VERSION ""

NS_ :

BS_:

BU_: INTERCEPTOR EON XXX

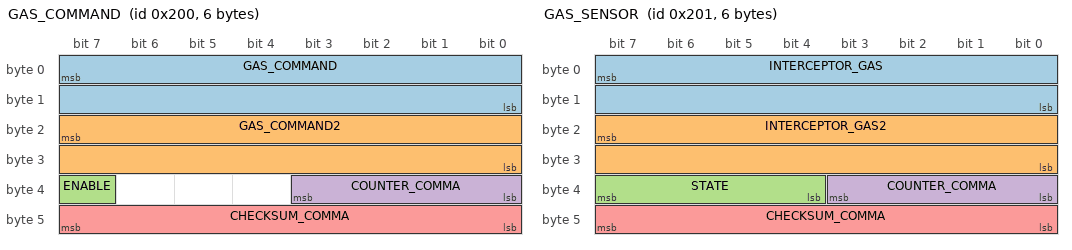
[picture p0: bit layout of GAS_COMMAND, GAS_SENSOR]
BO_ 512 GAS_COMMAND: 6 EON
 SG_ GAS_COMMAND : 7|16@0+ (0.253984064,-83.3) [0|1] "" INTERCEPTOR
 SG_ GAS_COMMAND2 : 23|16@0+ (0.126992032,-83.3) [0|1] "" INTERCEPTOR
 SG_ ENABLE : 39|1@0+ (1,0) [0|1] "" INTERCEPTOR
 SG_ COUNTER_COMMA : 35|4@0+ (1,0) [0|15] "" INTERCEPTOR
 SG_ CHECKSUM_COMMA : 47|8@0+ (1,0) [0|255] "" INTERCEPTOR

BO_ 513 GAS_SENSOR: 6 INTERCEPTOR
 SG_ INTERCEPTOR_GAS : 7|16@0+ (0.253984064,-83.3) [0|1] "" EON
 SG_ INTERCEPTOR_GAS2 : 23|16@0+ (0.126992032,-83.3) [0|1] "" EON
 SG_ STATE : 39|4@0+ (1,0) [0|15] "" EON
 SG_ COUNTER_COMMA : 35|4@0+ (1,0) [0|15] "" EON
 SG_ CHECKSUM_COMMA : 47|8@0+ (1,0) [0|255] "" EON

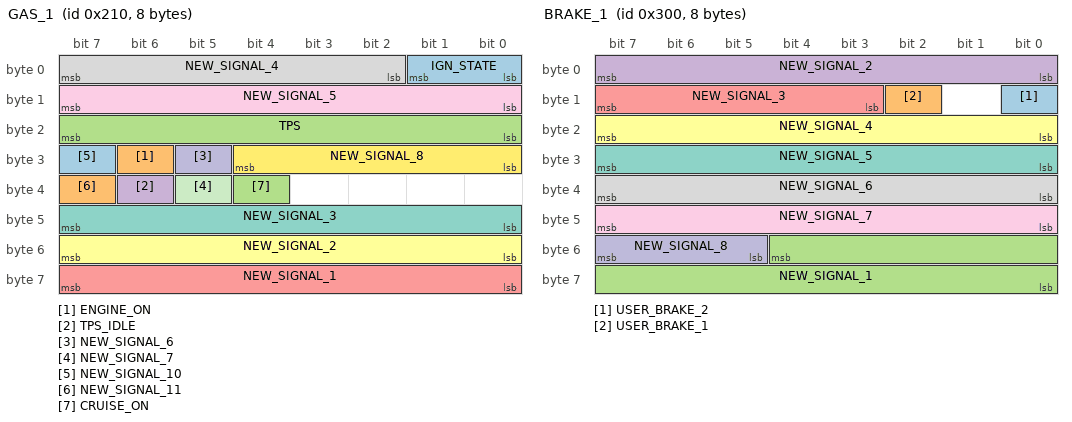
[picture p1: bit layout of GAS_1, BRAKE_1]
BO_ 528 GAS_1: 8 XXX
 SG_ IGN_STATE : 1|2@0+ (1,0) [0|1] "" XXX
 SG_ ENGINE_ON : 30|1@0+ (1,0) [0|1] "" XXX
 SG_ TPS : 23|8@0+ (1,0) [0|250] "" XXX
 SG_ TPS_IDLE : 38|1@0+ (1,0) [0|1] "" XXX
 SG_ NEW_SIGNAL_1 : 63|8@0+ (1,0) [0|1] "" XXX
 SG_ NEW_SIGNAL_2 : 55|8@0+ (1,0) [0|1] "" XXX
 SG_ NEW_SIGNAL_3 : 47|8@0+ (1,0) [0|1] "" XXX
 SG_ NEW_SIGNAL_4 : 7|6@0+ (1,0) [0|1] "" XXX
 SG_ NEW_SIGNAL_5 : 15|8@0+ (1,0) [0|1] "" XXX
 SG_ NEW_SIGNAL_6 : 29|1@0+ (1,0) [0|1] "" XXX
 SG_ NEW_SIGNAL_7 : 37|1@0+ (1,0) [0|1] "" XXX
 SG_ NEW_SIGNAL_8 : 28|5@0+ (1,0) [0|1] "" XXX
 SG_ NEW_SIGNAL_10 : 31|1@0+ (1,0) [0|1] "" XXX
 SG_ NEW_SIGNAL_11 : 39|1@0+ (1,0) [0|1] "" XXX
 SG_ CRUISE_ON : 36|1@0+ (1,0) [0|1] "" XXX

BO_ 768 BRAKE_1: 8 XXX
 SG_ USER_BRAKE_2 : 8|1@0+ (1,0) [0|1] "" XXX
 SG_ USER_BRAKE_1 : 10|1@1+ (1,0) [0|7] "" XXX
 SG_ NEW_SIGNAL_1 : 52|13@0- (1,0) [0|65535] "" XXX
 SG_ NEW_SIGNAL_2 : 7|8@0+ (1,0) [0|1] "" XXX
 SG_ NEW_SIGNAL_3 : 15|5@0+ (1,0) [0|1] "" XXX
 SG_ NEW_SIGNAL_4 : 23|8@0+ (1,0) [0|1] "" XXX
 SG_ NEW_SIGNAL_5 : 31|8@0+ (1,0) [0|1] "" XXX
 SG_ NEW_SIGNAL_6 : 39|8@0+ (1,0) [0|1] "" XXX
 SG_ NEW_SIGNAL_7 : 47|8@0+ (1,0) [0|1] "" XXX
 SG_ NEW_SIGNAL_8 : 55|3@0+ (1,0) [0|1] "" XXX

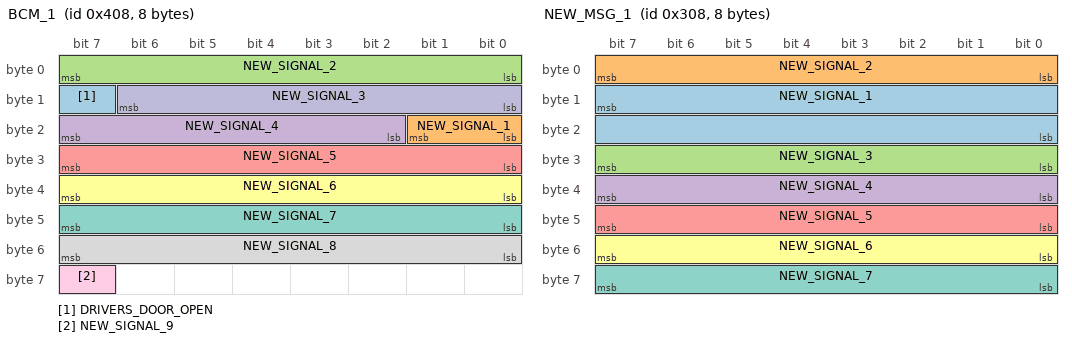
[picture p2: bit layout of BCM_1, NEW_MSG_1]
BO_ 1032 BCM_1: 8 XXX
 SG_ DRIVERS_DOOR_OPEN : 15|1@0+ (1,0) [0|1] "" XXX
 SG_ NEW_SIGNAL_1 : 16|2@1+ (1,0) [0|3] "" XXX
 SG_ NEW_SIGNAL_2 : 7|8@0+ (1,0) [0|1] "" XXX
 SG_ NEW_SIGNAL_4 : 23|6@0+ (1,0) [0|1] "" XXX
 SG_ NEW_SIGNAL_5 : 31|8@0+ (1,0) [0|1] "" XXX
 SG_ NEW_SIGNAL_6 : 39|8@0+ (1,0) [0|1] "" XXX
 SG_ NEW_SIGNAL_7 : 47|8@0+ (1,0) [0|1] "" XXX
 SG_ NEW_SIGNAL_8 : 55|8@0+ (1,0) [0|1] "" XXX
 SG_ NEW_SIGNAL_9 : 63|1@0+ (1,0) [0|1] "" XXX
 SG_ NEW_SIGNAL_3 : 14|7@0+ (1,0) [0|1] "" XXX

BO_ 1048 TRANS_1: 8 XXX
 SG_ NEW_SIGNAL_1 : 47|8@0+ (1,0) [0|16777215] "" XXX
 SG_ NEW_SIGNAL_3 : 53|6@0+ (1,0) [0|255] "" XXX
 SG_ NEW_SIGNAL_4 : 23|8@0+ (1,0) [0|255] "" XXX
 SG_ NEW_SIGNAL_6 : 31|8@0+ (1,0) [0|1] "" XXX
 SG_ NEW_SIGNAL_5 : 39|8@0+ (1,0) [0|1] "" XXX
 SG_ MODE_ASCII : 15|8@0+ (1,0) [0|255] "" XXX
 SG_ GEAR_ASCII : 7|8@0+ (1,0) [0|1] "" XXX
 SG_ NEW_SIGNAL_2 : 63|10@0+ (1,0) [0|255] "" XXX

BO_ 776 NEW_MSG_1: 8 XXX
 SG_ NEW_SIGNAL_1 : 15|16@0+ (1,0) [0|65535] "" XXX
 SG_ NEW_SIGNAL_2 : 7|8@0+ (1,0) [0|1] "" XXX
 SG_ NEW_SIGNAL_3 : 31|8@0+ (1,0) [0|1] "" XXX
 SG_ NEW_SIGNAL_4 : 39|8@0+ (1,0) [0|1] "" XXX
 SG_ NEW_SIGNAL_5 : 47|8@0+ (1,0) [0|1] "" XXX
 SG_ NEW_SIGNAL_6 : 55|8@0+ (1,0) [0|1] "" XXX
 SG_ NEW_SIGNAL_7 : 63|8@0+ (1,0) [0|1] "" XXX

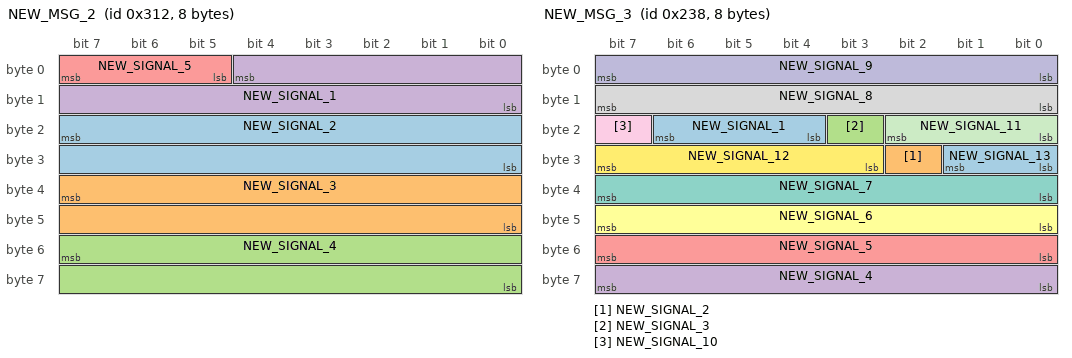
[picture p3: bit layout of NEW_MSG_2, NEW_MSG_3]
BO_ 786 NEW_MSG_2: 8 XXX
 SG_ NEW_SIGNAL_2 : 23|16@0+ (1,0) [0|65535] "" XXX
 SG_ NEW_SIGNAL_3 : 39|16@0+ (1,0) [0|65535] "" XXX
 SG_ NEW_SIGNAL_4 : 55|16@0+ (-1,0) [0|65535] "" XXX
 SG_ NEW_SIGNAL_1 : 4|13@0- (1,0) [0|65535] "" XXX
 SG_ NEW_SIGNAL_5 : 7|3@0+ (1,0) [0|1] "" XXX

BO_ 568 NEW_MSG_3: 8 XXX
 SG_ NEW_SIGNAL_1 : 22|3@0+ (1,0) [0|255] "" XXX
 SG_ NEW_SIGNAL_2 : 26|1@0+ (1,0) [0|1] "" XXX
 SG_ NEW_SIGNAL_3 : 19|1@0+ (1,0) [0|1] "" XXX
 SG_ NEW_SIGNAL_4 : 63|8@0+ (1,0) [0|255] "" XXX
 SG_ NEW_SIGNAL_5 : 55|8@0+ (1,0) [0|1] "" XXX
 SG_ NEW_SIGNAL_6 : 47|8@0+ (1,0) [0|1] "" XXX
 SG_ NEW_SIGNAL_7 : 39|8@0+ (1,0) [0|1] "" XXX
 SG_ NEW_SIGNAL_8 : 15|8@0+ (1,0) [0|1] "" XXX
 SG_ NEW_SIGNAL_10 : 23|1@0+ (1,0) [0|1] "" XXX
 SG_ NEW_SIGNAL_9 : 7|8@0+ (1,0) [0|1] "" XXX
 SG_ NEW_SIGNAL_11 : 18|3@0+ (1,0) [0|1] "" XXX
 SG_ NEW_SIGNAL_12 : 31|5@0+ (1,0) [0|1] "" XXX
 SG_ NEW_SIGNAL_13 : 25|2@0+ (1,0) [0|1] "" XXX

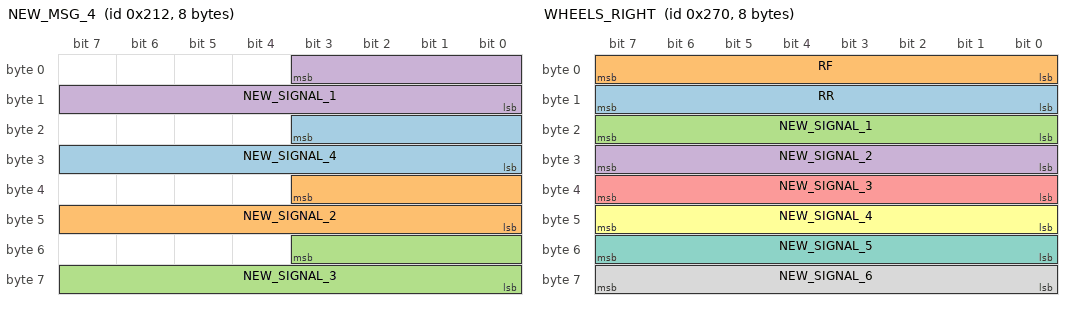
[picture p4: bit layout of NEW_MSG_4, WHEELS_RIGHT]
BO_ 530 NEW_MSG_4: 8 XXX
 SG_ NEW_SIGNAL_4 : 19|12@0+ (1,0) [0|65535] "" XXX
 SG_ NEW_SIGNAL_2 : 35|12@0+ (1,0) [0|65535] "" XXX
 SG_ NEW_SIGNAL_3 : 51|12@0+ (1,0) [0|15] "" XXX
 SG_ NEW_SIGNAL_1 : 3|12@0+ (1,0) [0|255] "" XXX

BO_ 520 NEW_MSG_5: 8 XXX
 SG_ NEW_SIGNAL_1 : 23|16@0+ (1,0) [0|65535] "" XXX
 SG_ NEW_SIGNAL_3 : 39|16@0+ (1,0) [0|65535] "" XXX
 SG_ NEW_SIGNAL_2 : 55|18@0+ (1,0) [0|255] "" XXX
 SG_ NEW_SIGNAL_4 : 7|16@0+ (1,0) [0|65535] "" XXX

BO_ 824 NEW_MSG_6: 8 XXX
 SG_ NEW_SIGNAL_1 : 51|14@0- (1,0) [0|65535] "" XXX
 SG_ NEW_SIGNAL_3 : 15|8@0+ (1,0) [0|1] "" XXX
 SG_ NEW_SIGNAL_4 : 23|8@0+ (1,0) [0|1] "" XXX
 SG_ NEW_SIGNAL_5 : 31|8@0+ (1,0) [0|1] "" XXX
 SG_ NEW_SIGNAL_6 : 39|8@0+ (1,0) [0|1] "" XXX
 SG_ NEW_SIGNAL_7 : 47|8@0+ (1,0) [0|1] "" XXX
 SG_ NEW_SIGNAL_8 : 55|4@0+ (1,0) [0|1] "" XXX
 SG_ NEW_SIGNAL_9 : 7|8@0+ (1,0) [0|255] "" XXX

BO_ 624 WHEELS_RIGHT: 8 XXX
 SG_ RR : 15|8@0+ (1,0) [0|257] "" XXX
 SG_ RF : 7|8@0+ (1,0) [0|255] "" XXX
 SG_ NEW_SIGNAL_1 : 23|8@0+ (1,0) [0|1] "" XXX
 SG_ NEW_SIGNAL_2 : 31|8@0+ (1,0) [0|1] "" XXX
 SG_ NEW_SIGNAL_3 : 39|8@0+ (1,0) [0|1] "" XXX
 SG_ NEW_SIGNAL_4 : 47|8@0+ (1,0) [0|1] "" XXX
 SG_ NEW_SIGNAL_5 : 55|8@0+ (1,0) [0|1] "" XXX
 SG_ NEW_SIGNAL_6 : 63|8@0+ (1,0) [0|1] "" XXX

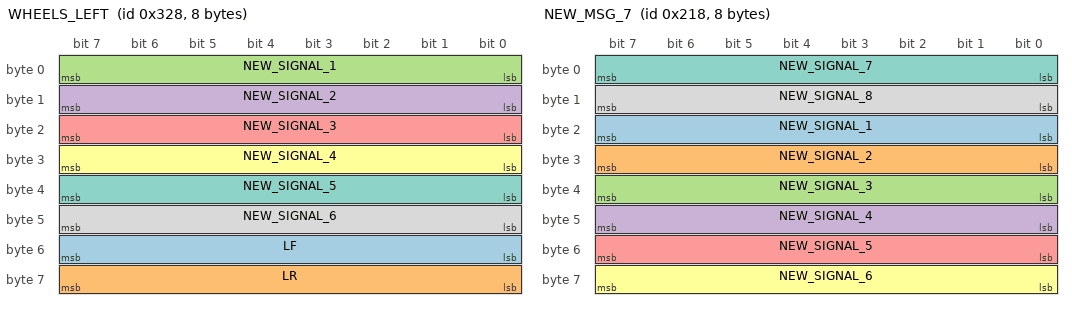
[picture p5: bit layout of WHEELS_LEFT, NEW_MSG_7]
BO_ 808 WHEELS_LEFT: 8 XXX
 SG_ LF : 55|8@0+ (1,0) [0|255] "" XXX
 SG_ LR : 63|8@0+ (1,0) [0|255] "" XXX
 SG_ NEW_SIGNAL_1 : 7|8@0+ (1,0) [0|1] "" XXX
 SG_ NEW_SIGNAL_2 : 15|8@0+ (1,0) [0|1] "" XXX
 SG_ NEW_SIGNAL_3 : 23|8@0+ (1,0) [0|1] "" XXX
 SG_ NEW_SIGNAL_4 : 31|8@0+ (1,0) [0|1] "" XXX
 SG_ NEW_SIGNAL_5 : 39|8@0+ (1,0) [0|1] "" XXX
 SG_ NEW_SIGNAL_6 : 47|8@0+ (1,0) [0|1] "" XXX

BO_ 560 BRAKE_2: 1 XXX
 SG_ NEW_SIGNAL_1 : 7|8@0+ (1,0) [0|255] "" XXX

BO_ 536 NEW_MSG_7: 8 XXX
 SG_ NEW_SIGNAL_1 : 23|8@0+ (1,0) [0|255] "" XXX
 SG_ NEW_SIGNAL_2 : 31|8@0+ (1,0) [0|65535] "" XXX
 SG_ NEW_SIGNAL_3 : 39|8@0+ (1,0) [0|255] "" XXX
 SG_ NEW_SIGNAL_4 : 47|8@0+ (1,0) [0|1] "" XXX
 SG_ NEW_SIGNAL_5 : 55|8@0+ (1,0) [0|1] "" XXX
 SG_ NEW_SIGNAL_6 : 63|8@0+ (1,0) [0|1] "" XXX
 SG_ NEW_SIGNAL_7 : 7|8@0+ (1,0) [0|1] "" XXX
 SG_ NEW_SIGNAL_8 : 15|8@0+ (1,0) [0|1] "" XXX

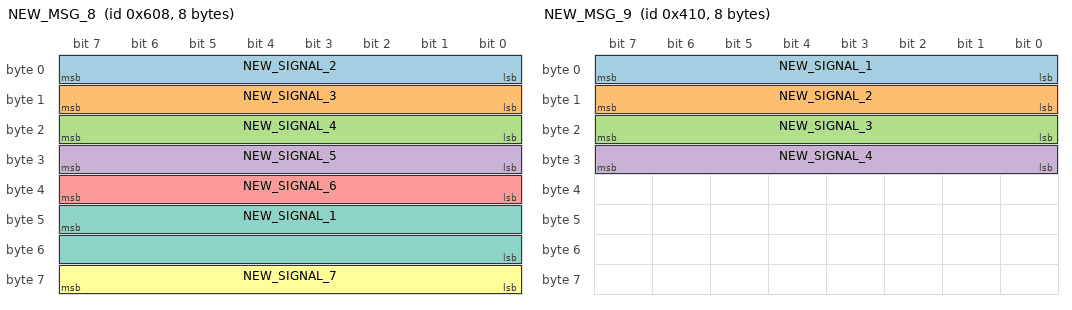
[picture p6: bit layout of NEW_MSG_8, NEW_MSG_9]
BO_ 1544 NEW_MSG_8: 8 XXX
 SG_ NEW_SIGNAL_2 : 7|8@0+ (1,0) [0|1] "" XXX
 SG_ NEW_SIGNAL_3 : 15|8@0+ (1,0) [0|1] "" XXX
 SG_ NEW_SIGNAL_4 : 23|8@0+ (1,0) [0|1] "" XXX
 SG_ NEW_SIGNAL_5 : 31|8@0+ (1,0) [0|1] "" XXX
 SG_ NEW_SIGNAL_6 : 39|8@0+ (1,0) [0|1] "" XXX
 SG_ NEW_SIGNAL_7 : 63|8@0+ (1,0) [0|1] "" XXX
 SG_ NEW_SIGNAL_1 : 47|16@0- (1,0) [0|1] "" XXX

BO_ 1040 NEW_MSG_9: 8 XXX
 SG_ NEW_SIGNAL_1 : 7|8@0+ (1,0) [0|1] "" XXX
 SG_ NEW_SIGNAL_2 : 15|8@0+ (1,0) [0|1] "" XXX
 SG_ NEW_SIGNAL_3 : 23|8@0+ (1,0) [0|1] "" XXX
 SG_ NEW_SIGNAL_4 : 31|8@0+ (1,0) [0|1] "" XXX

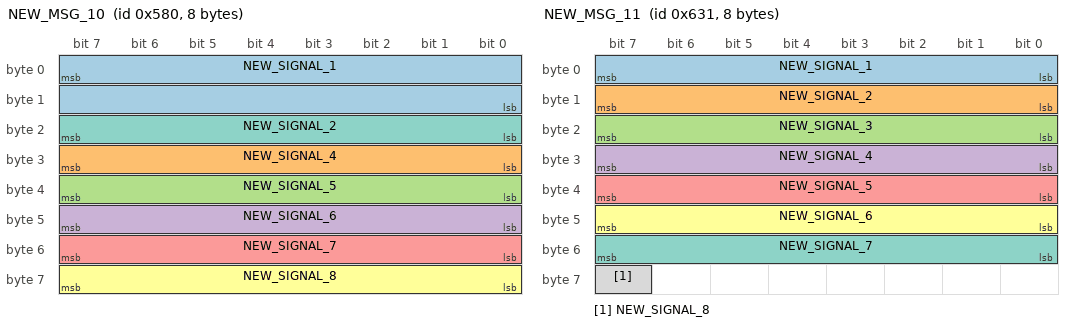
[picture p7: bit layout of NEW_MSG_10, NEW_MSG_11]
BO_ 1408 NEW_MSG_10: 8 XXX
 SG_ NEW_SIGNAL_1 : 7|16@0+ (1,0) [0|1] "" XXX
 SG_ NEW_SIGNAL_4 : 31|8@0+ (1,0) [0|1] "" XXX
 SG_ NEW_SIGNAL_5 : 39|8@0+ (1,0) [0|1] "" XXX
 SG_ NEW_SIGNAL_6 : 47|8@0+ (1,0) [0|1] "" XXX
 SG_ NEW_SIGNAL_7 : 55|8@0+ (1,0) [0|1] "" XXX
 SG_ NEW_SIGNAL_8 : 63|8@0+ (1,0) [0|1] "" XXX
 SG_ NEW_SIGNAL_2 : 23|8@0+ (1,0) [0|1] "" XXX

BO_ 1585 NEW_MSG_11: 8 XXX
 SG_ NEW_SIGNAL_1 : 7|8@0+ (1,0) [0|1] "" XXX
 SG_ NEW_SIGNAL_2 : 15|8@0+ (1,0) [0|1] "" XXX
 SG_ NEW_SIGNAL_3 : 23|8@0+ (1,0) [0|1] "" XXX
 SG_ NEW_SIGNAL_4 : 31|8@0+ (1,0) [0|1] "" XXX
 SG_ NEW_SIGNAL_5 : 39|8@0+ (1,0) [0|1] "" XXX
 SG_ NEW_SIGNAL_6 : 47|8@0+ (1,0) [0|1] "" XXX
 SG_ NEW_SIGNAL_7 : 55|8@0+ (1,0) [0|1] "" XXX
 SG_ NEW_SIGNAL_8 : 63|1@0+ (1,0) [0|1] "" XXX

CM_ SG_ 528 IGN_STATE "0=STARTING,1=ENGINE_ON,2=ENGINE_OFF";
